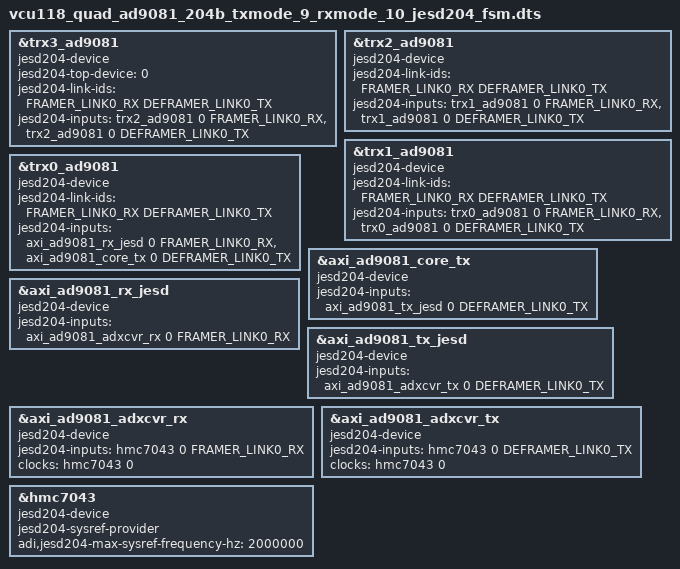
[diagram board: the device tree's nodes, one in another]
// SPDX-License-Identifier: GPL-2.0
/*
 * dts file for QUAD AD9081-FMC-EBZ on Xilinx ZynqMP ZCU102 Rev 1.0
 *
 * Copyright (C) 2019-2020 Analog Devices Inc.
 */

#include "vcu118_quad_ad9081_204b_txmode_9_rxmode_10.dts"

#include <dt-bindings/iio/adc/adi,ad9081.h>

&trx3_ad9081 {
	jesd204-device;
	#jesd204-cells = <2>;
	jesd204-top-device = <0>; /* This is the TOP device */
	jesd204-link-ids = < FRAMER_LINK0_RX DEFRAMER_LINK0_TX>;

	jesd204-inputs =
		<&trx2_ad9081 0 FRAMER_LINK0_RX>,
		<&trx2_ad9081 0 DEFRAMER_LINK0_TX>;
};

&trx2_ad9081 {
	jesd204-device;
	#jesd204-cells = <2>;
	jesd204-link-ids = < FRAMER_LINK0_RX DEFRAMER_LINK0_TX>;

	jesd204-inputs =
		<&trx1_ad9081 0 FRAMER_LINK0_RX>,
		<&trx1_ad9081 0 DEFRAMER_LINK0_TX>;
};

&trx1_ad9081 {
	jesd204-device;
	#jesd204-cells = <2>;
	jesd204-link-ids = < FRAMER_LINK0_RX DEFRAMER_LINK0_TX>;

	jesd204-inputs =
		<&trx0_ad9081 0 FRAMER_LINK0_RX>,
		<&trx0_ad9081 0 DEFRAMER_LINK0_TX>;
};

&trx0_ad9081 {
	jesd204-device;
	#jesd204-cells = <2>;
	jesd204-link-ids = < FRAMER_LINK0_RX DEFRAMER_LINK0_TX>;

	jesd204-inputs =
		<&axi_ad9081_rx_jesd 0 FRAMER_LINK0_RX>,
		<&axi_ad9081_core_tx 0 DEFRAMER_LINK0_TX>;
};

&axi_ad9081_core_tx {
	jesd204-device;
	#jesd204-cells = <2>;
	jesd204-inputs = <&axi_ad9081_tx_jesd 0 DEFRAMER_LINK0_TX>;
};

&axi_ad9081_rx_jesd {
	jesd204-device;
	#jesd204-cells = <2>;
	jesd204-inputs = <&axi_ad9081_adxcvr_rx 0 FRAMER_LINK0_RX>;
};

&axi_ad9081_tx_jesd {
	jesd204-device;
	#jesd204-cells = <2>;
	jesd204-inputs = <&axi_ad9081_adxcvr_tx 0 DEFRAMER_LINK0_TX>;
};

&axi_ad9081_adxcvr_rx {
	jesd204-device;
	#jesd204-cells = <2>;
	jesd204-inputs =  <&hmc7043 0 FRAMER_LINK0_RX>;
	clocks = <&hmc7043 0>; /* div40 is controlled by axi_ad9081_rx_jesd */
	clock-names = "conv";
};

&axi_ad9081_adxcvr_tx {
	jesd204-device;
	#jesd204-cells = <2>;
	jesd204-inputs =  <&hmc7043 0 DEFRAMER_LINK0_TX>;
	clocks = <&hmc7043 0>; /* div40 is controlled by axi_ad9081_tx_jesd */
	clock-names = "conv";
};

&hmc7043 {
	jesd204-device;
	#jesd204-cells = <2>;
	jesd204-sysref-provider;

	adi,jesd204-max-sysref-frequency-hz = <2000000>;
};
